# XMC4300 register map
Vendor: Infineon; File version: 0.5.1 (Superset device XMC4800)
CPU: CM4 r2p0, little endian, MPU, FPU, 6 interrupt priority bits
Registers are 32-bit, read-write, reset 0x0 unless marked. A register's access mark holds for its fields unless they carry their own. Offsets are from the block's base; [hi:lo] are bit positions; 'fields as' and 'values as' point back to an identical list.

## GPDMA0_CH0 — General Purpose DMA Unit 0
Base 0x50014000
Same registers: GPDMA0_CH1 0x50014058
0x00 SAR — Source Address Register
  [31:0] SAR — Current Source Address of DMA transfer
0x08 DAR — Destination Address Register
  [31:0] DAR — Current Destination address of DMA transfer
0x10 LLP — Linked List Pointer Register
  [31:2] LOC — Starting Address In Memory
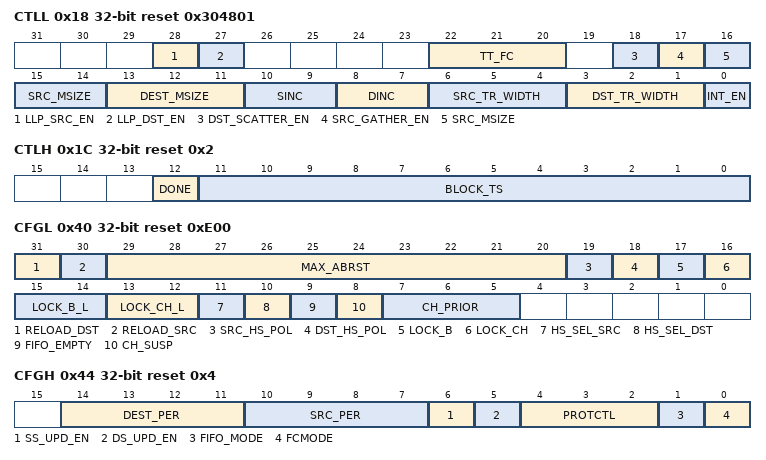
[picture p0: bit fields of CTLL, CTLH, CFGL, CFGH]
0x18 CTLL reset 0x304801 — Control Register Low
  [28] LLP_SRC_EN — Linked List Pointer for Source Enable
  [27] LLP_DST_EN — Linked List Pointer for Destination Enable
  [22:20] TT_FC — Transfer Type and Flow Control
  [18] DST_SCATTER_EN — Destination scatter enable
    0=Scatter disabled; 1=Scatter enabled
  [17] SRC_GATHER_EN — Source gather enable
    0=Gather disabled; 1=Gather enabled
  [16:14] SRC_MSIZE — Source Burst Transaction Length
  [13:11] DEST_MSIZE — Destination Burst Transaction Length
  [10:9] SINC — Source Address Increment
    0=Increment; 1=Decrement; 2=No change
  [8:7] DINC — Destination Address Increment
    0=Increment; 1=Decrement; 2=No change
  [6:4] SRC_TR_WIDTH — Source Transfer Width
  [3:1] DST_TR_WIDTH — Destination Transfer Width
  [0] INT_EN — Interrupt Enable Bit
0x1C CTLH reset 0x2 — Control Register High
  [12] DONE — Done bit
  [11:0] BLOCK_TS — Block Transfer Size
0x20 SSTAT — Source Status Register
  [31:0] SSTAT — Source Status
0x28 DSTAT — Destination Status Register
  [31:0] DSTAT — Destination Status
0x30 SSTATAR — Source Status Address Register
  [31:0] SSTATAR — Source Status Address
0x38 DSTATAR — Destination Status Address Register
  [31:0] DSTATAR — Destination Status Address
0x40 CFGL access per field reset 0xE00 (reset mask 0xFFFFFF0F) — Configuration Register Low
  [31] RELOAD_DST rw — Automatic Destination Reload
  [30] RELOAD_SRC rw — Automatic Source Reload
  [29:20] MAX_ABRST rw — Maximum AMBA Burst Length
  [19] SRC_HS_POL rw — Source Handshaking Interface Polarity
    0=Active high; 1=Active low
  [18] DST_HS_POL rw — Destination Handshaking Interface Polarity
    0=Active high; 1=Active low
  [17] LOCK_B rw — Bus Lock Bit
  [16] LOCK_CH rw — Channel Lock Bit
  [15:14] LOCK_B_L rw — Bus Lock Level
    0=Over complete DMA transfer; 1=Over complete DMA block transfer; 2=Over complete DMA transaction
  [13:12] LOCK_CH_L rw — Channel Lock Level
    values as LOCK_B_L
  [11] HS_SEL_SRC rw — Source Software or Hardware Handshaking Select
    0=Hardware handshaking interface. Software-initiated transaction requests are ignored.; 1=Software handshaking interface. Hardware-initiated transaction requests are ignored.
  [10] HS_SEL_DST rw — Destination Software or Hardware Handshaking Select
    0=Hardware handshaking interface. Software-initiated transaction requests are ignored.; 1=Software handshaking interface. Hardware- initiated transaction requests are ignored.
  [9] FIFO_EMPTY ro — Indicates if there is data left in the channel FIFO
    1=Channel FIFO empty; 0=Channel FIFO not empty
  [8] CH_SUSP rw — Channel Suspend
    0=Not suspended; 1=Suspend DMA transfer from the source
  [7:5] CH_PRIOR rw — Channel priority
0x44 CFGH reset 0x4 — Configuration Register High
  [14:11] DEST_PER — Destination Peripheral
  [10:7] SRC_PER — Source Peripheral
  [6] SS_UPD_EN — Source Status Update Enable
  [5] DS_UPD_EN — Destination Status Update Enable
  [4:2] PROTCTL — Protection Control
  [1] FIFO_MODE — FIFO Mode Select
    0=Space/data available for single AHB transfer of the specified transfer width; 1=Data available is greater than or equal to half the FIFO depth for destination transfers and space available is greater than half the fifo depth for source transfers. The exceptions are at the end of a burst transaction request or at the end of a block transfer.
  [0] FCMODE — Flow Control Mode
    0=Source transaction requests are serviced when they occur. Data pre-fetching is enabled.; 1=Source transaction requests are not serviced until a destination transaction request occurs. In this mode, the amount of data transferred from the source is limited so that it is guaranteed to be transferred to the destination prior to block termination by the destination. Data pre-fetching is disabled.
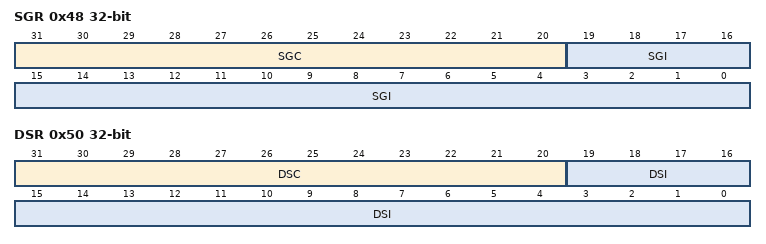
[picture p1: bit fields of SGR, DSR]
0x48 SGR — Source Gather Register
  [31:20] SGC — Source gather count
  [19:0] SGI — Source gather interval
0x50 DSR — Destination Scatter Register
  [31:20] DSC — Destination scatter count
  [19:0] DSI — Destination scatter interval
